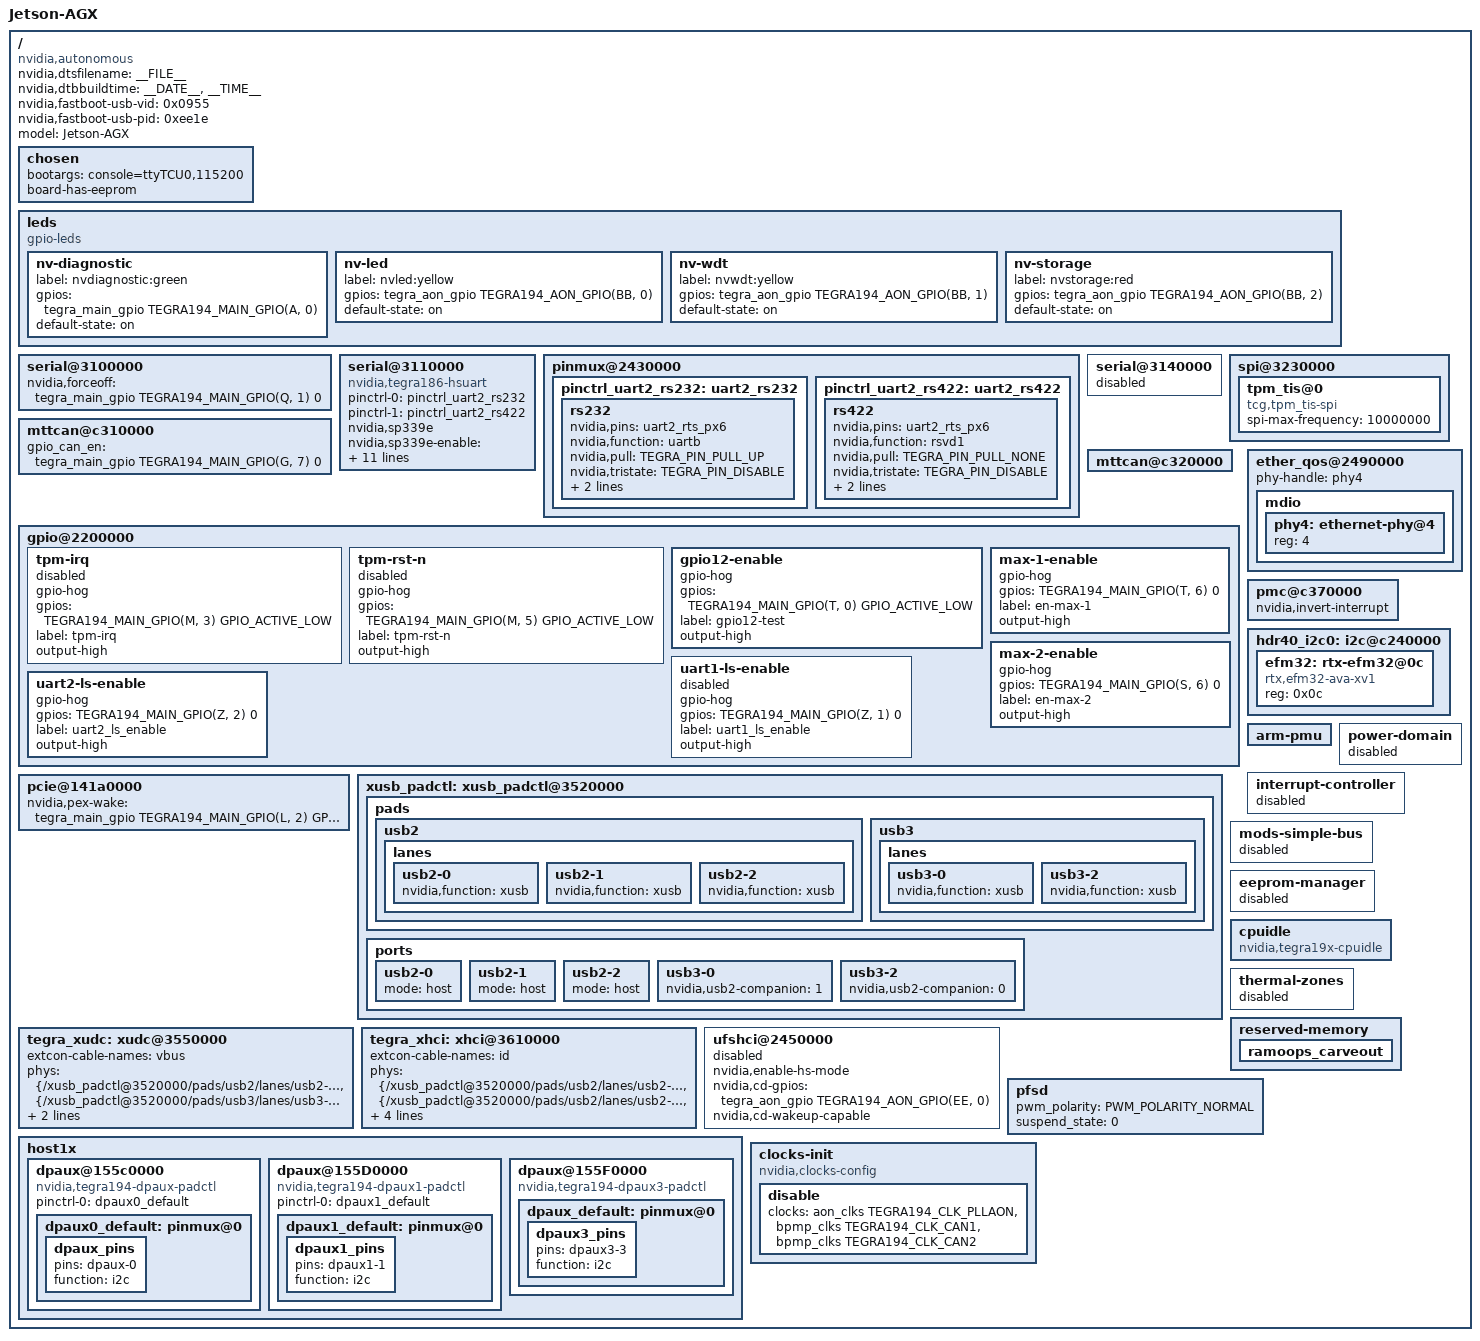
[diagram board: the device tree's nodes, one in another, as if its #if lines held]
/*
 * Common include DTS file for CVM:P2888-0001 and CVB:ava-xv1 variants.
 *
 * Copyright (c) 2018-2020, NVIDIA CORPORATION.  All rights reserved.
 *
 * This program is free software; you can redistribute it and/or modify
 * it under the terms of the GNU General Public License as published by
 * the Free Software Foundation; version 2 of the License.
 *
 * This program is distributed in the hope that it will be useful, but WITHOUT
 * ANY WARRANTY; without even the implied warranty of MERCHANTABILITY or
 * FITNESS FOR A PARTICULAR PURPOSE.  See the GNU General Public License for
 * more details.
 */

#include "dt-bindings/extcon-ids.h"
#include "dt-bindings/gpio/tegra194-gpio.h"
#include "tegra194-p2888-0000-a00.dtsi"
#include <t19x-common-platforms/tegra194-platforms-eqos.dtsi>
#include "tegra194-ava-xv1-a00.dtsi"
#include "tegra194-power-tree-p2888-0001-ava-xv1.dtsi"
#include <t19x-common-platforms/tegra194-comms.dtsi>
#include "tegra194-thermal-p2888.dtsi"
#include <t19x-common-platforms/tegra194-no-pll-aon-clock.dtsi>

/ {
	nvidia,dtsfilename = __FILE__;
	nvidia,dtbbuildtime = __DATE__, __TIME__;
	nvidia,fastboot-usb-vid = <0x0955>;
	nvidia,fastboot-usb-pid = <0xee1e>;
	model = "Jetson-AGX";
	compatible = "nvidia,autonomous", "nvidia,tegra194";

	chosen {
		bootargs ="console=ttyTCU0,115200";
		board-has-eeprom;
	};

	leds {
		compatible = "gpio-leds";
		status = "okay";

		nv-diagnostic {
			label = "nvdiagnostic:green";
			gpios = <&tegra_main_gpio TEGRA194_MAIN_GPIO(A, 0) GPIO_ACTIVE_HIGH>;
			default-state = "on";
		};
		nv-led {
			label = "nvled:yellow";
			gpios = <&tegra_aon_gpio TEGRA194_AON_GPIO(BB, 0) GPIO_ACTIVE_HIGH>;
			default-state = "on";
		};
		nv-wdt {
			label = "nvwdt:yellow";
			gpios = <&tegra_aon_gpio TEGRA194_AON_GPIO(BB, 1) GPIO_ACTIVE_HIGH>;
			default-state = "on";
		};
		nv-storage {
			label = "nvstorage:red";
			gpios = <&tegra_aon_gpio TEGRA194_AON_GPIO(BB, 2) GPIO_ACTIVE_HIGH>;
			default-state = "on";
		};
	};

	serial@3100000 {	//Enable UART1
		nvidia,forceoff	     = <&tegra_main_gpio TEGRA194_MAIN_GPIO(Q, 1) 0> ;
		status = "okay";
	};

	serial@3110000 {	//Enable UART2
		compatible = "nvidia,tegra186-hsuart";
		pinctrl-names = "rs232", "rs422";
		pinctrl-0 = <&pinctrl_uart2_rs232>;
		pinctrl-1 = <&pinctrl_uart2_rs422>;
		nvidia,sp339e;
		nvidia,sp339e-enable = <&tegra_main_gpio TEGRA194_MAIN_GPIO(Q, 4) 0> ;
		nvidia,sp339e-m0     = <&tegra_main_gpio TEGRA194_MAIN_GPIO(P, 4) 0> ;
		nvidia,sp339e-m1     = <&tegra_main_gpio TEGRA194_MAIN_GPIO(P, 5) 0> ;
		nvidia,sp339e-tm     = <&tegra_main_gpio TEGRA194_MAIN_GPIO(P, 6) 0> ;
		nvidia,sp339e-dir    = <&tegra_main_gpio TEGRA194_MAIN_GPIO(X, 6) 0> ;
		nvidia,sp339e-slew   = <&tegra_main_gpio TEGRA194_MAIN_GPIO(Q, 7) 0> ;
		status = "okay";
	};

	pinmux@2430000 {
		pinctrl_uart2_rs232: uart2_rs232 {
			rs232 {
				nvidia,pins = "uart2_rts_px6";
				nvidia,function = "uartb";
				nvidia,pull = <TEGRA_PIN_PULL_UP>;
				nvidia,tristate = <TEGRA_PIN_DISABLE>;
				nvidia,enable-input = <TEGRA_PIN_DISABLE>;
				nvidia,lpdr = <TEGRA_PIN_DISABLE>;
			};
		};
		pinctrl_uart2_rs422: uart2_rs422 {
			rs422 {
				nvidia,pins = "uart2_rts_px6";
				nvidia,function = "rsvd1";
				nvidia,pull = <TEGRA_PIN_PULL_NONE>;
				nvidia,tristate = <TEGRA_PIN_DISABLE>;
				nvidia,enable-input = <TEGRA_PIN_DISABLE>;
				nvidia,lpdr = <TEGRA_PIN_DISABLE>;
			};
		};
	};

	serial@3140000 {	//Disable UART5
		status = "disabled";
	};

	spi@3230000 {		//Enable SPI3
		status = "okay";
		tpm_tis@0 {
		        compatible = "tcg,tpm_tis-spi";
		        spi-max-frequency = <10000000>;
		};
	};

	mttcan@c310000 {	//Enable Can0
		status = "okay";
		gpio_can_en = <&tegra_main_gpio TEGRA194_MAIN_GPIO(G, 7)  0>;
	};

	mttcan@c320000 {	//Enable Can1
		status = "okay";
	};

	gpio@2200000 {
		tpm-irq {
			gpio-hog;
			gpios = <TEGRA194_MAIN_GPIO(M, 3) GPIO_ACTIVE_LOW>;
			label = "tpm-irq";
			output-high;
			status = "disabled";
		};
		tpm-rst-n {
			gpio-hog;
			gpios = <TEGRA194_MAIN_GPIO(M, 5) GPIO_ACTIVE_LOW>;
			label = "tpm-rst-n";
			output-high;
			status = "disabled";
		};
		gpio12-enable {
			gpio-hog;
			gpios = <TEGRA194_MAIN_GPIO(T, 0) GPIO_ACTIVE_LOW>;
			label = "gpio12-test";
			output-high;
			status = "okay";
		};
		max-1-enable {
			gpio-hog;
			gpios = <TEGRA194_MAIN_GPIO(T, 6) 0>;
			label = "en-max-1";
			output-high;
			status = "okay";
		};
		max-2-enable {
			gpio-hog;
			gpios = <TEGRA194_MAIN_GPIO(S, 6) 0>;
			label = "en-max-2";
			output-high;
			status = "okay";
		};
		uart1-ls-enable {
			gpio-hog;
			gpios = <TEGRA194_MAIN_GPIO(Z, 1) 0>;
			label = "uart1_ls_enable";
			output-high;
			status = "disabled";
		};
		uart2-ls-enable {
			gpio-hog;
			gpios = <TEGRA194_MAIN_GPIO(Z, 2) 0>;
			label = "uart2_ls_enable";
			output-high;
			status = "okay";
		};
	};

        ether_qos@2490000 {
		phy-handle = <&phy4>;
		mdio {
			phy4: ethernet-phy@4 {
				reg = <4>;
			};
		};
	};

	pcie@141a0000 {		//PCIE - C5
		status = "okay";
		nvidia,pex-wake = <&tegra_main_gpio TEGRA194_MAIN_GPIO(L, 2)
					GPIO_ACTIVE_HIGH>;
	};

	pmc@c370000 {
		nvidia,invert-interrupt;
	};

	hdr40_i2c0: i2c@c240000 {
		efm32: rtx-efm32@0c {
			compatible = "rtx,efm32-ava-xv1";
			reg = <0x0c>;
			status = "okay";
		};
	};

#if TEGRA_XUSB_PADCONTROL_VERSION >= DT_VERSION_2

	xusb_padctl: xusb_padctl@3520000 {
		status = "okay";

		pads {
			usb2 {
				lanes {
					usb2-0 {
						nvidia,function = "xusb";
						status = "okay";
					};
					usb2-1 {
						nvidia,function = "xusb";
						status = "okay";
					};
					usb2-2 {
						nvidia,function = "xusb";
						status = "okay";
					};
				};
			};
			usb3 {
				lanes {
					usb3-0 {
						nvidia,function = "xusb";
						status = "okay";
					};
					usb3-2 {
						nvidia,function = "xusb";
						status = "okay";
					};
				};
			};
		};

		ports {
			usb2-0 {
				mode = "host";
				status = "okay";
			};
			usb2-1 {
				mode = "host";
				status = "okay";
			};
			usb2-2 {
				mode = "host";
				status = "okay";
			};
			usb3-0 {
				nvidia,usb2-companion = <1>;
				status = "okay";
			};
			usb3-2 {
				nvidia,usb2-companion = <0>;
				status = "okay";
			};
		};
	};
#endif

	tegra_xudc: xudc@3550000 {
		extcon-cable-names = "vbus";
		#extcon-cells = <1>;
		phys = <&{/xusb_padctl@3520000/pads/usb2/lanes/usb2-0}>,
			<&{/xusb_padctl@3520000/pads/usb3/lanes/usb3-2}>;
		phy-names = "usb2", "usb3";
		nvidia,xusb-padctl = <&xusb_padctl>;
		nvidia,boost_cpu_freq = <1200>;
		status = "okay";
	};

	tegra_xhci: xhci@3610000 {
		extcon-cable-names = "id";
		#extcon-cells = <1>;
		phys = <&{/xusb_padctl@3520000/pads/usb2/lanes/usb2-0}>,
			<&{/xusb_padctl@3520000/pads/usb2/lanes/usb2-1}>,
			<&{/xusb_padctl@3520000/pads/usb2/lanes/usb2-2}>,
			<&{/xusb_padctl@3520000/pads/usb3/lanes/usb3-0}>,
			<&{/xusb_padctl@3520000/pads/usb3/lanes/usb3-2}>;
		phy-names = "usb2-0", "usb2-1", "usb2-2",
			"usb3-0", "usb3-2";
		nvidia,xusb-padctl = <&xusb_padctl>;
		status = "okay";
	};

	arm-pmu {
		status = "okay";
	};

	power-domain {
		status = "disabled";
	};

	interrupt-controller {
		status = "disabled";
	};

	mods-simple-bus {
		status = "disabled";
	};

	eeprom-manager {
		status = "disabled";
	};

	cpuidle {
		compatible = "nvidia,tegra19x-cpuidle";
		status = "okay";
	};

	thermal-zones {
		status = "disabled";
	};

	reserved-memory {
		ramoops_carveout {
			status = "okay";
		};
	};

	ufshci@2450000 {
		status = "disabled";
		nvidia,enable-hs-mode;
		nvidia,cd-gpios = <&tegra_aon_gpio TEGRA194_AON_GPIO(EE, 0) GPIO_ACTIVE_HIGH>;
		nvidia,cd-wakeup-capable;
	};

	pfsd {
		pwm_polarity= <PWM_POLARITY_NORMAL>;
		suspend_state = <0>;
	};

	host1x {
		dpaux@155c0000 {
			status = "okay";
			pinctrl-names = "default";
			pinctrl-0 = <&dpaux0_default>;
			compatible = "nvidia,tegra194-dpaux-padctl";
			/delete-property/ power-domains;
			dpaux0_default: pinmux@0 {
				dpaux_pins {
					pins = "dpaux-0";
					function = "i2c";
				};
			};
		};

		dpaux@155D0000 {
			status = "okay";
			pinctrl-names = "default";
			pinctrl-0 = <&dpaux1_default>;
			compatible = "nvidia,tegra194-dpaux1-padctl";
			/delete-property/ power-domains;
			dpaux1_default: pinmux@0 {
				dpaux1_pins {
					pins = "dpaux1-1";
					function = "i2c";
				};
			};
		};

		dpaux@155F0000 {
			status = "okay";
			compatible = "nvidia,tegra194-dpaux3-padctl";
			/delete-property/ power-domains;
			dpaux_default: pinmux@0 {
				dpaux3_pins {
					pins = "dpaux3-3";
					function = "i2c";
				};
			};
		};
	};

	clocks-init {
		compatible = "nvidia,clocks-config";
		status = "okay";
		disable {
			clocks = <&aon_clks TEGRA194_CLK_PLLAON>,
				<&bpmp_clks TEGRA194_CLK_CAN1>,
				<&bpmp_clks TEGRA194_CLK_CAN2>;
		};
	};
};

#if LINUX_VERSION >= 414
#include <tegra194-linux-4.14.dtsi>
#endif
